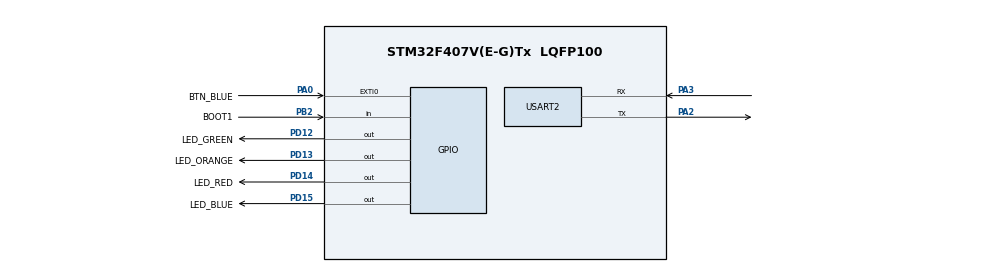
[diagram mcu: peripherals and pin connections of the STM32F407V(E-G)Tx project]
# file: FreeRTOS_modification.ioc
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Dma.Request0=USART2_RX
Dma.USART2_RX.0.Direction=DMA_PERIPH_TO_MEMORY
Dma.USART2_RX.0.FIFOMode=DMA_FIFOMODE_DISABLE
Dma.USART2_RX.0.Instance=DMA1_Stream5
Dma.USART2_RX.0.MemDataAlignment=DMA_MDATAALIGN_BYTE
Dma.USART2_RX.0.MemInc=DMA_MINC_ENABLE
Dma.USART2_RX.0.Mode=DMA_NORMAL
Dma.USART2_RX.0.PeriphDataAlignment=DMA_PDATAALIGN_BYTE
Dma.USART2_RX.0.PeriphInc=DMA_PINC_DISABLE
Dma.USART2_RX.0.Priority=DMA_PRIORITY_LOW
FREERTOS.INCLUDE_vTaskDelayUntil=1
FREERTOS.Tasks01=unusedTask,8,128,StartDefaultTask,Default,NULL,Dynamic,NULL,NULL
FREERTOS.configGENERATE_RUN_TIME_STATS=1
FREERTOS.configUSE_STATS_FORMATTING_FUNCTIONS=0
FREERTOS.configUSE_TRACE_FACILITY=1
Mcu.Family=STM32F4
Mcu.Name=STM32F407V(E-G)Tx
Mcu.Package=LQFP100
NVIC.DMA1_Stream5_IRQn=true\:5\:0\:false\:false\:true\:true\:false\:true
NVIC.PriorityGroup=NVIC_PRIORITYGROUP_4
NVIC.TIM8_TRG_COM_TIM14_IRQn=true\:0\:0\:false\:false\:true\:false\:false\:true
NVIC.TimeBase=TIM8_TRG_COM_TIM14_IRQn
NVIC.TimeBaseIP=TIM14
PA0-WKUP.GPIO_Label=BTN_BLUE
PA0-WKUP.GPIO_ModeDefaultEXTI=GPIO_MODE_EVT_RISING
PA0-WKUP.GPIO_PuPd=GPIO_NOPULL
PA0-WKUP.Signal=GPXTI0
PA13.GPIO_Label=SWDIO
PA13.Mode=Serial_Wire
PA13.Signal=SYS_JTMS-SWDIO
PA14.GPIO_Label=SWCLK
PA14.Mode=Serial_Wire
PA14.Signal=SYS_JTCK-SWCLK
PA2.Mode=Asynchronous
PA2.Signal=USART2_TX
PA3.Mode=Asynchronous
PA3.Signal=USART2_RX
PB2.GPIO_Label=BOOT1
PB2.GPIO_Mode=GPIO_MODE_INPUT
PB2.GPIO_PuPd=GPIO_NOPULL
PB2.Signal=GPIO_Input
PB3.GPIO_Label=SWO
PB3.Signal=SYS_JTDO-SWO
PC14-OSC32_IN.GPIO_Label=PC14-OSC32_IN
PC14-OSC32_IN.Mode=LSE-External-Oscillator
PC14-OSC32_IN.Signal=RCC_OSC32_IN
PC15-OSC32_OUT.GPIO_Label=PC15-OSC32_OUT
PC15-OSC32_OUT.Mode=LSE-External-Oscillator
PC15-OSC32_OUT.Signal=RCC_OSC32_OUT
PD12.GPIO_Label=LED_GREEN
PD12.GPIO_PuPd=GPIO_NOPULL
PD12.GPIO_Speed=GPIO_SPEED_FREQ_LOW
PD12.Signal=GPIO_Output
PD13.GPIO_Label=LED_ORANGE
PD13.GPIO_PuPd=GPIO_NOPULL
PD13.GPIO_Speed=GPIO_SPEED_FREQ_LOW
PD13.Signal=GPIO_Output
PD14.GPIO_Label=LED_RED
PD14.GPIO_PuPd=GPIO_NOPULL
PD14.GPIO_Speed=GPIO_SPEED_FREQ_LOW
PD14.Signal=GPIO_Output
PD15.GPIO_Label=LED_BLUE
PD15.GPIO_PuPd=GPIO_NOPULL
PD15.GPIO_Speed=GPIO_SPEED_FREQ_LOW
PD15.Signal=GPIO_Output
PH0-OSC_IN.GPIO_Label=PH0-OSC_IN
PH0-OSC_IN.Mode=HSE-External-Oscillator
PH0-OSC_IN.Signal=RCC_OSC_IN
PH1-OSC_OUT.GPIO_Label=PH1-OSC_OUT
PH1-OSC_OUT.Mode=HSE-External-Oscillator
PH1-OSC_OUT.Signal=RCC_OSC_OUT
ProjectManager.HeapSize=0x200
ProjectManager.StackSize=0x400
ProjectManager.TargetToolchain=SW4STM32
RCC.48MHZClocksFreq_Value=48000000
RCC.AHBFreq_Value=168000000
RCC.APB1CLKDivider=RCC_HCLK_DIV4
RCC.APB1Freq_Value=42000000
RCC.APB1TimFreq_Value=84000000
RCC.APB2CLKDivider=RCC_HCLK_DIV2
RCC.APB2Freq_Value=84000000
RCC.APB2TimFreq_Value=168000000
RCC.CortexFreq_Value=168000000
RCC.HCLKFreq_Value=168000000
RCC.HSE_VALUE=8000000
RCC.HSI_VALUE=16000000
RCC.PLLM=8
RCC.PLLN=336
RCC.PLLQ=7
RCC.PLLSourceVirtual=RCC_PLLSOURCE_HSE
RCC.SYSCLKFreq_VALUE=168000000
RCC.SYSCLKSource=RCC_SYSCLKSOURCE_PLLCLK
RCC.VCOOutputFreq_Value=336000000
TIM2.AutoReloadPreload=TIM_AUTORELOAD_PRELOAD_ENABLE
TIM2.Period=0xFFFFFFFF
TIM2.Prescaler=8399
USART2.VirtualMode=VM_ASYNC
VP_CRC_VS_CRC.Mode=CRC_Activate
VP_FREERTOS_VS_CMSIS_V2.Mode=CMSIS_V2
VP_SYS_VS_tim14.Mode=TIM14
VP_TIM2_VS_ClockSourceINT.Mode=Internal
board=STM32F4DISCOVERY

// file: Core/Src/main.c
/* USER CODE BEGIN Header */
/**
 ******************************************************************************
 * @file           : main.c
 * @brief          : Main program body
 ******************************************************************************
 * @attention
 *
 * <h2><center>&copy; Copyright (c) 2020 STMicroelectronics.
 * All rights reserved.</center></h2>
 *
 * This software component is licensed by ST under Ultimate Liberty license
 * SLA0044, the "License"; You may not use this file except in compliance with
 * the License. You may obtain a copy of the License at:
 *                             www.st.com/SLA0044
 *
 ******************************************************************************
 */
/* USER CODE END Header */

#include "main.h"
#include "cmsis_os.h"
#include "crc.h"
#include "dma.h"
#include "tim.h"
#include "usart.h"
#include "gpio.h"

/* USER CODE BEGIN Includes */

#include "example.h"
#include <ndebug_printf.h>
/* USER CODE END Includes */

/* USER CODE BEGIN PV */
void SystemClock_Config (void);
#if 0
/* USER CODE END PV */

void SystemClock_Config(void);
void MX_FREERTOS_Init(void);
/* USER CODE BEGIN PFP */
#endif
/* USER CODE END PFP */

int main (void)
{

    /* MCU Configuration--------------------------------------------------------*/

    /* Reset of all peripherals, Initializes the Flash interface and the Systick. */
    HAL_Init();

    /* Configure the system clock */
    SystemClock_Config();

    /* Initialize all configured peripherals */
    MX_GPIO_Init();
    MX_DMA_Init();
    MX_CRC_Init();
    MX_USART2_UART_Init();
    MX_TIM2_Init();
    /* USER CODE BEGIN 2 */

    ndebug_printf("FreeRTOS Modification.\n");

    example_run();

    /* WARNING: NEVER REACHED */
    /* WARNING: NEVER REACHED */
    /* WARNING: NEVER REACHED */

#if 0
    /* USER CODE END 2 */

    /* Call init function for freertos objects (in freertos.c) */
    MX_FREERTOS_Init();

    /* Start scheduler */
    osKernelStart();

    /* We should never get here as control is now taken by the scheduler */

    /* Infinite loop */
    /* USER CODE BEGIN WHILE */
#endif
    while (1)
    {
        /* USER CODE END WHILE */

    }
}

void SystemClock_Config (void)
{
    RCC_OscInitTypeDef RCC_OscInitStruct = { 0 };
    RCC_ClkInitTypeDef RCC_ClkInitStruct = { 0 };

    /** Configure the main internal regulator output voltage
     */
    __HAL_RCC_PWR_CLK_ENABLE()
    ;
    __HAL_PWR_VOLTAGESCALING_CONFIG(PWR_REGULATOR_VOLTAGE_SCALE1);
    /** Initializes the CPU, AHB and APB busses clocks
     */
    RCC_OscInitStruct.OscillatorType = RCC_OSCILLATORTYPE_HSE;
    RCC_OscInitStruct.HSEState = RCC_HSE_ON;
    RCC_OscInitStruct.PLL.PLLState = RCC_PLL_ON;
    RCC_OscInitStruct.PLL.PLLSource = RCC_PLLSOURCE_HSE;
    RCC_OscInitStruct.PLL.PLLM = 8;
    RCC_OscInitStruct.PLL.PLLN = 336;
    RCC_OscInitStruct.PLL.PLLP = RCC_PLLP_DIV2;
    RCC_OscInitStruct.PLL.PLLQ = 7;
    if (HAL_RCC_OscConfig( &RCC_OscInitStruct) != HAL_OK)
    {
        Error_Handler();
    }
    /** Initializes the CPU, AHB and APB busses clocks
     */
    RCC_ClkInitStruct.ClockType = RCC_CLOCKTYPE_HCLK | RCC_CLOCKTYPE_SYSCLK
            | RCC_CLOCKTYPE_PCLK1 | RCC_CLOCKTYPE_PCLK2;
    RCC_ClkInitStruct.SYSCLKSource = RCC_SYSCLKSOURCE_PLLCLK;
    RCC_ClkInitStruct.AHBCLKDivider = RCC_SYSCLK_DIV1;
    RCC_ClkInitStruct.APB1CLKDivider = RCC_HCLK_DIV4;
    RCC_ClkInitStruct.APB2CLKDivider = RCC_HCLK_DIV2;

    if (HAL_RCC_ClockConfig( &RCC_ClkInitStruct, FLASH_LATENCY_5) != HAL_OK)
    {
        Error_Handler();
    }
}

void HAL_TIM_PeriodElapsedCallback (TIM_HandleTypeDef *htim)
{
    if (htim->Instance == TIM14)
    {
        HAL_IncTick();
    }
}

void Error_Handler (void)
{
}

/************************ (C) COPYRIGHT STMicroelectronics *****END OF FILE****/

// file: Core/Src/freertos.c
/* USER CODE BEGIN Header */
/**
  ******************************************************************************
  * File Name          : freertos.c
  * Description        : Code for freertos applications
  ******************************************************************************
  * @attention
  *
  * <h2><center>&copy; Copyright (c) 2020 STMicroelectronics.
  * All rights reserved.</center></h2>
  *
  * This software component is licensed by ST under Ultimate Liberty license
  * SLA0044, the "License"; You may not use this file except in compliance with
  * the License. You may obtain a copy of the License at:
  *                             www.st.com/SLA0044
  *
  ******************************************************************************
  */
/* USER CODE END Header */

#include "FreeRTOS.h"
#include "task.h"
#include "main.h"
#include "cmsis_os.h"

osThreadId_t unusedTaskHandle;

void StartDefaultTask(void *argument); // for v2

void MX_FREERTOS_Init(void); /* (MISRA C 2004 rule 8.1) */

void MX_FREERTOS_Init(void) {
osKernelInitialize(); // Initialize CMSIS-RTOS

  /* Create the thread(s) */
  /* definition and creation of unusedTask */
  const osThreadAttr_t unusedTask_attributes = {
    .name = "unusedTask",
    .priority = (osPriority_t) osPriorityLow,
    .stack_size = 128
  };
  unusedTaskHandle = osThreadNew(StartDefaultTask, NULL, &unusedTask_attributes);

}

void StartDefaultTask(void *argument)
{

  for(;;)
  {
    osDelay(1);
  }
}

/************************ (C) COPYRIGHT STMicroelectronics *****END OF FILE****/
